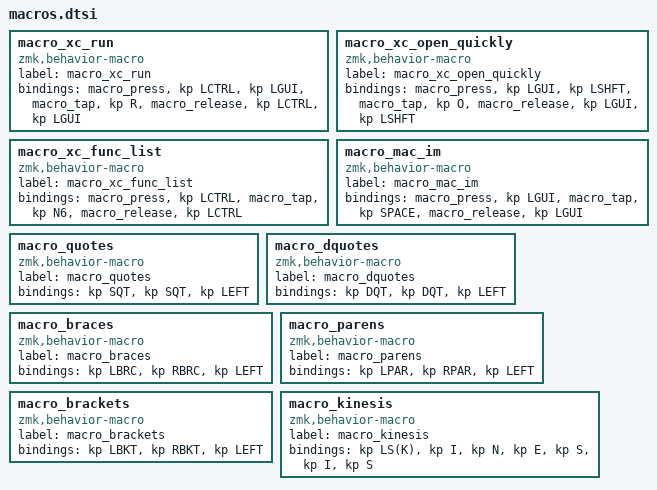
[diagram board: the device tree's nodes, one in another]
macro_xc_run: macro_xc_run{
compatible = "zmk,behavior-macro";
label = "macro_xc_run";
#binding-cells = <0>;
bindings = <&macro_press &kp LCTRL &kp LGUI>, <&macro_tap &kp R>, <&macro_release &kp LCTRL &kp LGUI>;
};
macro_xc_open_quickly: macro_xc_open_quickly{
compatible = "zmk,behavior-macro";
label = "macro_xc_open_quickly";
#binding-cells = <0>;
bindings = <&macro_press &kp LGUI &kp LSHFT>, <&macro_tap &kp O>, <&macro_release &kp LGUI &kp LSHFT>;
};
macro_xc_func_list: macro_xc_func_list{
compatible = "zmk,behavior-macro";
label = "macro_xc_func_list";
#binding-cells = <0>;
bindings = <&macro_press &kp LCTRL>, <&macro_tap &kp N6>, <&macro_release &kp LCTRL>;
};
macro_mac_im: macro_mac_im{
compatible = "zmk,behavior-macro";
label = "macro_mac_im";
#binding-cells = <0>;
bindings = <&macro_press &kp LGUI>, <&macro_tap &kp SPACE>, <&macro_release &kp LGUI>;
};
macro_quotes: macro_quotes{
compatible = "zmk,behavior-macro";
label = "macro_quotes";
#binding-cells = <0>;
bindings = <&kp SQT>, <&kp SQT>, <&kp LEFT>;
};
macro_dquotes: macro_dquotes{
compatible = "zmk,behavior-macro";
label = "macro_dquotes";
#binding-cells = <0>;
bindings = <&kp DQT>, <&kp DQT>, <&kp LEFT>;
};
macro_braces: macro_braces{
compatible = "zmk,behavior-macro";
label = "macro_braces";
#binding-cells = <0>;
bindings = <&kp LBRC>, <&kp RBRC>, <&kp LEFT>;
};
macro_parens: macro_parens{
compatible = "zmk,behavior-macro";
label = "macro_parens";
#binding-cells = <0>;
bindings = <&kp LPAR>, <&kp RPAR>, <&kp LEFT>;
};
macro_brackets: macro_brackets{
compatible = "zmk,behavior-macro";
label = "macro_brackets";
#binding-cells = <0>;
bindings = <&kp LBKT>, <&kp RBKT>, <&kp LEFT>;
};
macro_kinesis: macro_kinesis{
compatible = "zmk,behavior-macro";
label = "macro_kinesis";
#binding-cells = <0>;
bindings = <&kp LS(K)>, <&kp I>, <&kp N>, <&kp E>, <&kp S>, <&kp I>, <&kp S>;
};
